# STM32L052 register map
File version: 1.0
CPU: CM0+ r0p0, little endian, MPU, no FPU, 4 interrupt priority bits
Registers are 32-bit, read-write, reset 0x0 unless marked. A register's access mark holds for its fields unless they carry their own. Offsets are from the block's base; [hi:lo] are bit positions; {n}, {i} and the like mark numbered series.

## DAC — Digital-to-analog converter
Base 0x40007400
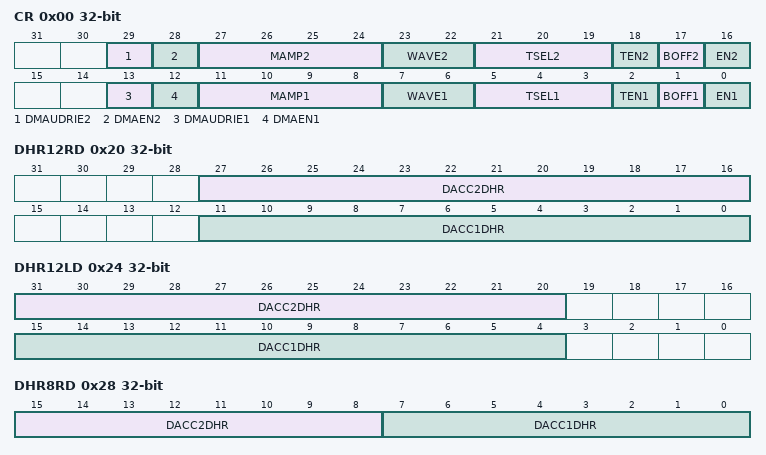
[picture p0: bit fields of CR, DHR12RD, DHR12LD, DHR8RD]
0x00 CR — control register
  [29] DMAUDRIE2 — DAC channel2 DMA underrun interrupt enable
  [28] DMAEN2 — DAC channel2 DMA enable
  [27:24] MAMP2 — DAC channel2 mask/amplitude selector
  [23:22] WAVE2 — DAC channel2 noise/triangle wave generation enable
  [21:19] TSEL2 — DAC channel2 trigger selection
  [18] TEN2 — DAC channel2 trigger enable
  [17] BOFF2 — DAC channel2 output buffer disable
  [16] EN2 — DAC channel2 enable
  [13] DMAUDRIE1 — DAC channel1 DMA Underrun Interrupt enable
  [12] DMAEN1 — DAC channel1 DMA enable
  [11:8] MAMP1 — DAC channel1 mask/amplitude selector
  [7:6] WAVE1 — DAC channel1 noise/triangle wave generation enable
  [5:3] TSEL1 — DAC channel1 trigger selection
  [2] TEN1 — DAC channel1 trigger enable
  [1] BOFF1 — DAC channel1 output buffer disable
  [0] EN1 — DAC channel1 enable
0x04 SWTRIGR wo — software trigger register
  [0] SWTRIG1 — DAC channel1 software trigger
0x08 DHR12R1 — channel1 12-bit right-aligned data holding register
  [11:0] DACC1DHR — DAC channel1 12-bit right-aligned data
0x0C DHR12L1 — channel1 12-bit left-aligned data holding register
  [15:4] DACC1DHR — DAC channel1 12-bit left-aligned data
0x10 DHR8R1 — channel1 8-bit right-aligned data holding register
  [7:0] DACC1DHR — DAC channel1 8-bit right-aligned data
0x14 DHR12R2 — channel2 12-bit right-aligned data holding register
  [11:0] DACC2DHR — DAC channel2 12-bit right-aligned data
0x18 DHR12L2 — channel2 12-bit left-aligned data holding register
  [15:4] DACC2DHR — DAC channel2 12-bit left-aligned data
0x1C DHR8R2 — channel2 8-bit right-aligned data holding register
  [7:0] DACC2DHR — DAC channel2 8-bit right-aligned data
0x20 DHR12RD — Dual DAC 12-bit right-aligned data holding register
  [27:16] DACC2DHR — DAC channel2 12-bit right-aligned data
  [11:0] DACC1DHR — DAC channel1 12-bit right-aligned data
0x24 DHR12LD — Dual DAC 12-bit left-aligned data holding register
  [31:20] DACC2DHR — DAC channel2 12-bit left-aligned data
  [15:4] DACC1DHR — DAC channel1 12-bit left-aligned data
0x28 DHR8RD — Dual DAC 8-bit right-aligned data holding register
  [15:8] DACC2DHR — DAC channel2 8-bit right-aligned data
  [7:0] DACC1DHR — DAC channel1 8-bit right-aligned data
0x2C DOR1 ro — channel1 data output register
  [11:0] DACC1DOR — DAC channel1 data output
0x30 DOR2 ro — channel2 data output register
  [11:0] DACC2DOR — DAC channel2 data output
0x34 SR — status register
  [13] DMAUDR1 — DAC channel1 DMA underrun flag

## GPIOA — General-purpose I/Os
Base 0x50000000
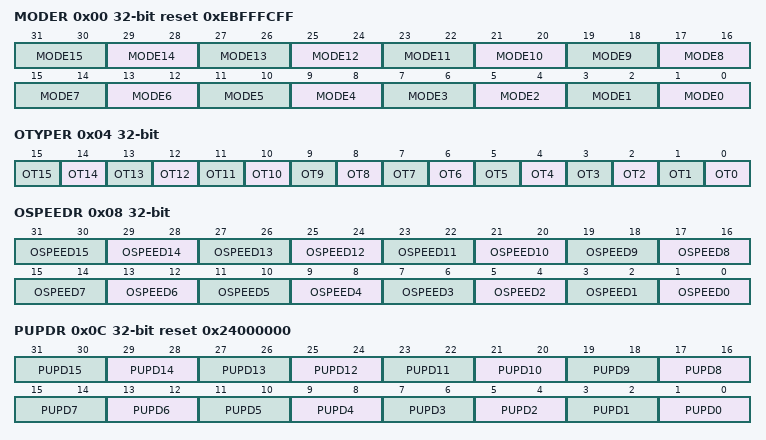
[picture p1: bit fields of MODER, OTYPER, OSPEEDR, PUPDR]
0x00 MODER reset 0xEBFFFCFF — GPIO port mode register
  [2n+1:2n] MODE{n} (n=0..15) — Port x configuration bits (y = 0..15)
0x04 OTYPER — GPIO port output type register
  [n] OT{n} (n=0..15) — Port x configuration bits (y = 0..15)
0x08 OSPEEDR — GPIO port output speed register
  [2n+1:2n] OSPEED{n} (n=0..15) — Port x configuration bits (y = 0..15)
0x0C PUPDR reset 0x24000000 — GPIO port pull-up/pull-down register
  [2n+1:2n] PUPD{n} (n=0..15) — Port x configuration bits (y = 0..15)
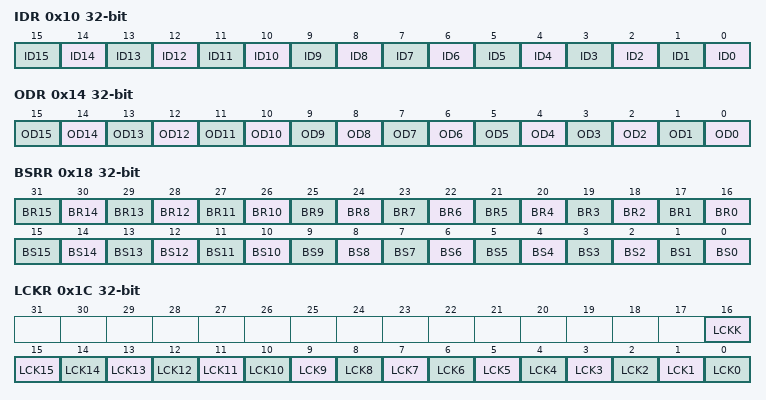
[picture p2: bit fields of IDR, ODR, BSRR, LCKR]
0x10 IDR ro — GPIO port input data register
  [n] ID{n} (n=0..15) — Port input data bit (y = 0..15)
0x14 ODR — GPIO port output data register
  [n] OD{n} (n=0..15) — Port output data bit (y = 0..15)
0x18 BSRR wo — GPIO port bit set/reset register
  [n+16] BR{n} (n=0..15) — Port x reset bit y (y = 0..15)
  [n] BS{n} (n=0..15) — Port x set bit y (y= 0..15)
0x1C LCKR — GPIO port configuration lock register
  [16] LCKK — Port x lock bit y (y= 0..15)
  [n] LCK{n} (n=0..15) — Port x lock bit y (y= 0..15)
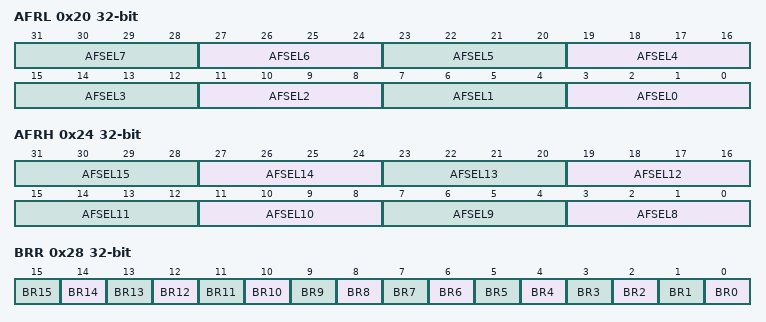
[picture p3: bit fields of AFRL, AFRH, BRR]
0x20 AFRL — GPIO alternate function low register
  [4n+3:4n] AFSEL{n} (n=0..7) — Alternate function selection for port x pin y (y = 0..7)
0x24 AFRH — GPIO alternate function high register
  [4n-29:4n-32] AFSEL{n} (n=8..15) — Alternate function selection for port x pin y (y = 8..15)
0x28 BRR wo — GPIO port bit reset register
  [n] BR{n} (n=0..15) — Port x Reset bit y (y= 0 .. 15)

## GPIOB — General-purpose I/Os
Base 0x50000400
Same registers: GPIOC 0x50000800
Registers as GPIOA; these are added or differ:
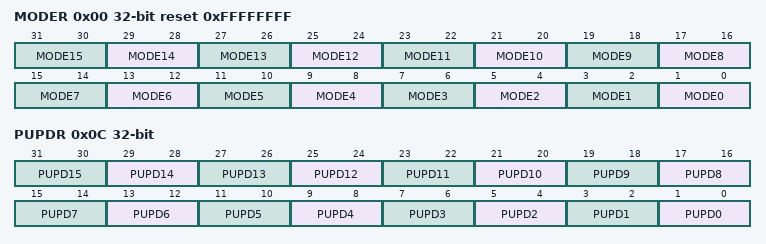
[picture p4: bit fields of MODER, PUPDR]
0x00 MODER reset 0xFFFFFFFF — GPIO port mode register
  [2n+1:2n] MODE{n} (n=0..15) — Port x configuration bits (y = 0..15)
0x0C PUPDR — GPIO port pull-up/pull-down register
  [2n+1:2n] PUPD{n} (n=0..15) — Port x configuration bits (y = 0..15)
